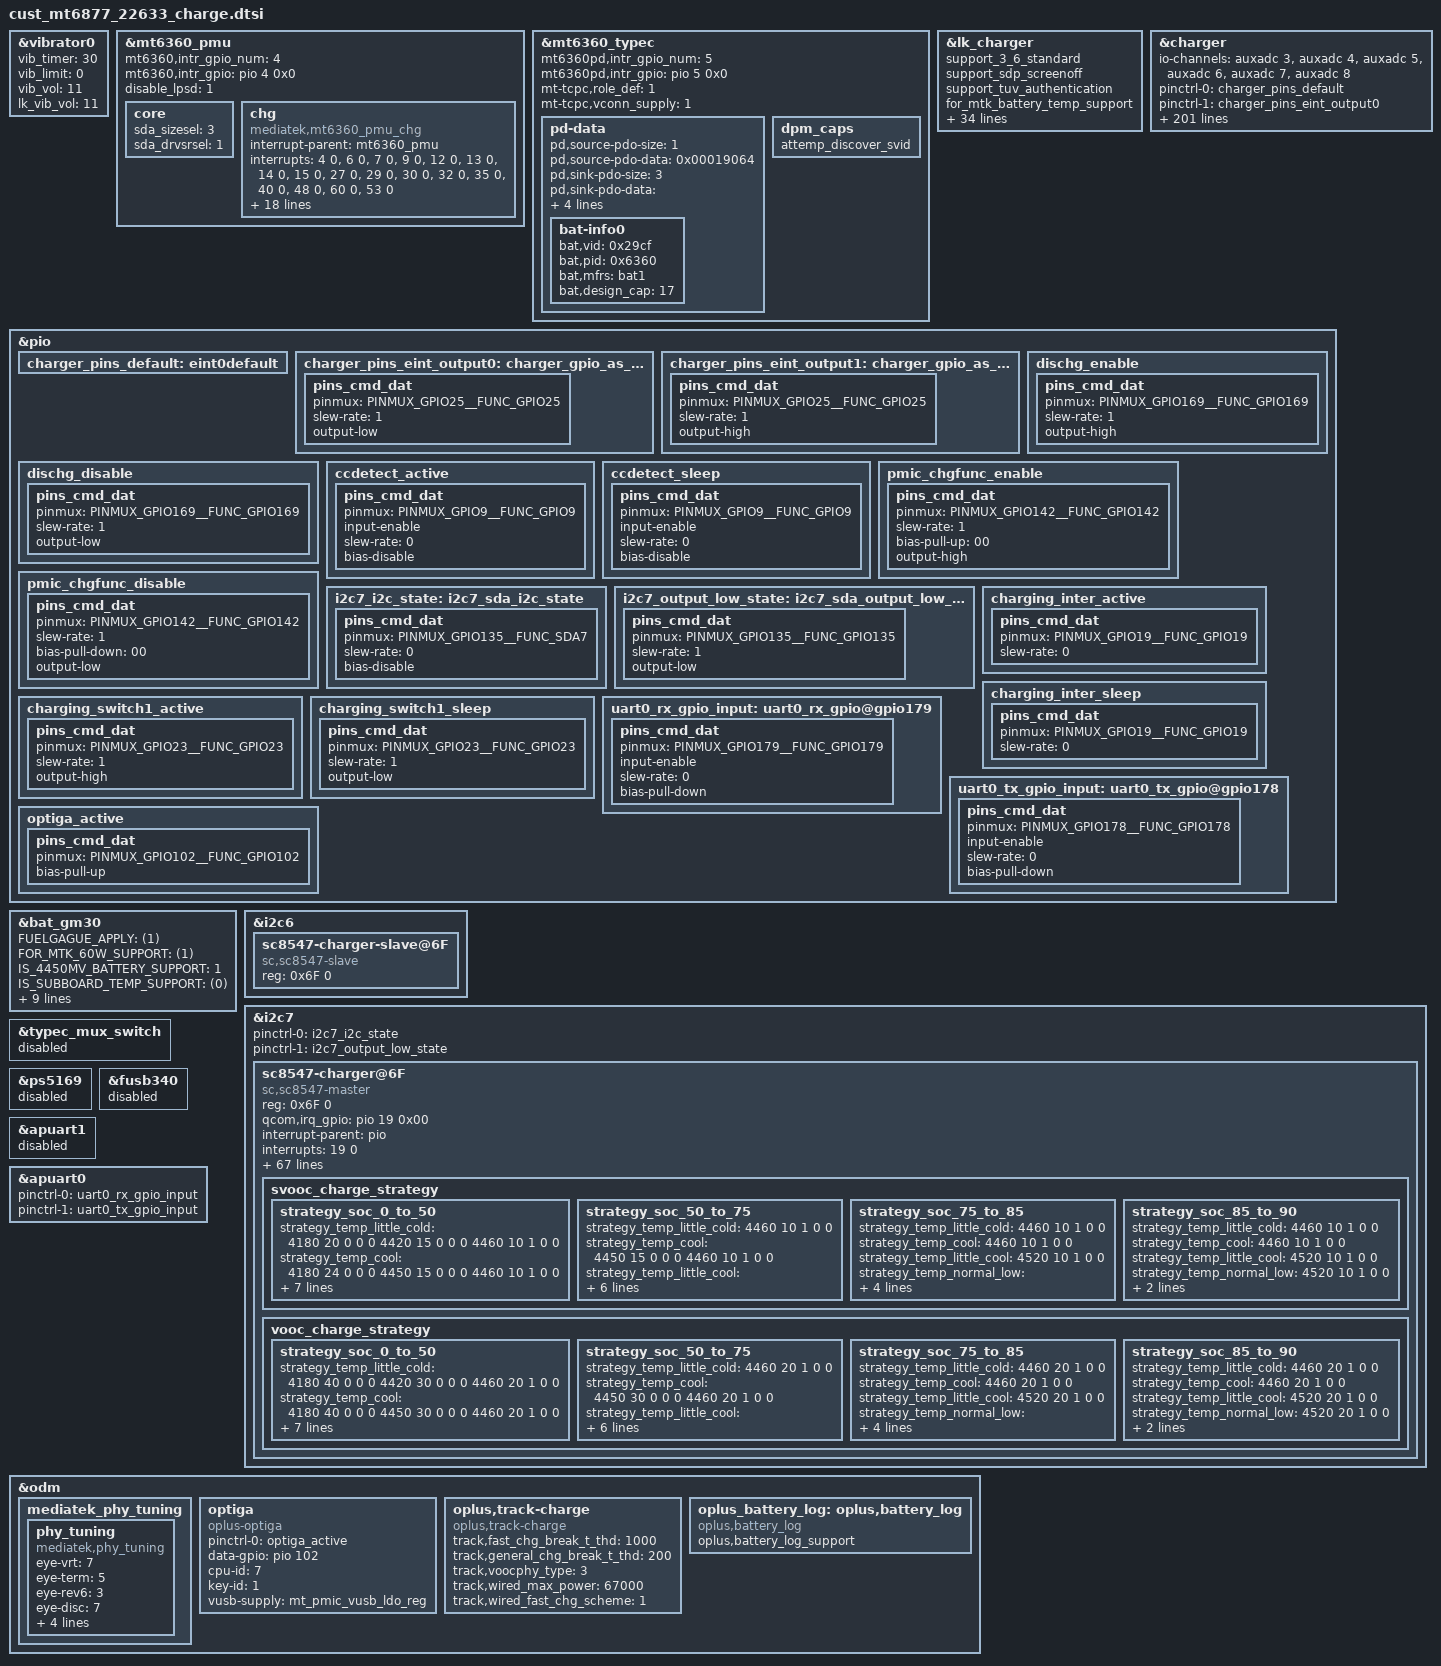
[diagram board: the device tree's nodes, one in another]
// SPDX-License-Identifier: GPL-2.0-only
/*
* Copyright (C) 2020-2021 Oplus. All rights reserved.
*/

//#ifdef OPLUS_FEATURE_CHG_BASIC
/*
 *
 * CPU:				--> MT6877
 * GPIO:
 * PERIEN_CHG_ENB		--> GPIO135(active - low)
 * MT6360_SCL			--> GPIO107(SCL5)
 * MT6360_SDA			--> GPIO108(SDA5)
 * EINT_SUBPMIC_IRQB    --> GPIO04
 * EINT_SUBPMIC_PD_IRQB --> GPIO05
 * CP1_SCL			    --> GPIO111(SCL7)
 * CP1_SDA			    --> GPIO112(SDA7)
 * CP2_SCL			    --> GPIO141(SCL9)
 * CP2_SDA			    --> GPIO142(SDA9)
 * CP1_INT			    --> GPIO19
 * USB_SWITCH1		    --> GPIO23
 * USB_SWITCH2 		    --> GPIO25
 * SEC_IC 		        --> GPIO102
 *
 * AP_UTXD0			    --> GPIO62
 * AP_URXD0			    --> GPIO61
 *
 * USB_ACC_INT			--> GPIO09
 * VBUS_SHORT			--> GPIO169
 *
 *
 * AUXADC:
 * 3				    --> AUX_IN2_CHARGER_NTC
 * 4				    --> AUX_IN2_BATTERY_NTC
 * 5				    --> AUX_IN4_USB_TEM_ADC_2
 * 6				    --> AUX_IN5_USB_TEM_ADC_1
 * 7				    --> AUX_IN3_BATT_ID(33W)/USB_CONN(67W)
 * 8				    --> AUX_IN6_NTC_BTB
 *
 *******************************************
 *
 * main pmic:			--> MT6365
 * charge pmic:			--> MT6360
 * charge ic:			--> MT6360
 * CP:				    --> HL7138
 * GAUGE:			    --> MT6365
 */

&vibrator0 {
	vib_timer = <30>;
	vib_limit = <0>;
	vib_vol= <11>;
	lk_vib_vol  = <11>;
	status = "okay";
};

&mt6360_pmu {
	mt6360,intr_gpio_num = <4>; /* direct defined GPIO num */
	mt6360,intr_gpio = <&pio 4 0x0>;
	disable_lpsd = <1>;

	core {
		sda_sizesel = <3>;
		sda_drvsrsel = <1>;
	};

	chg {
		compatible = "mediatek,mt6360_pmu_chg";
		interrupt-parent = <&mt6360_pmu>;
		interrupts = <4 0>, <6 0>, <7 0>, <9 0>,
				<12 0>, <13 0>, <14 0>, <15 0>,
				<27 0>, <29 0>, <30 0>, <32 0>,
				<35 0>, <40 0>, <48 0>, <60 0>,
				<53 0>;
		interrupt-names = "chg_treg_evt", "chg_mivr_evt",
				"pwr_rdy_evt", "chg_batsysuv_evt",
				"chg_vsysuv_evt", "chg_vsysov_evt",
				"chg_vbatov_evt", "chg_vbusov_evt",
				"chg_tmri", "chg_adpbadi",
				"chg_rvpi",  "chg_aiccmeasl",
				"wdtmri", "pumpx_donei",
				"attachi", "chrdet_ext_evt",
				"hvdcp_det";
		io-channels = <&adc 0>, <&adc 1>, <&adc 3>, <&adc 4>,
				<&adc 5>, <&adc 6>, <&adc 8>, <&adc 10>;
		io-channel-names = "USBID", "VBUSDIV5", "VSYS", "VBAT",
				"IBUS", "IBAT", "TEMP_JC", "TS";
		chg_name = "primary_chg";
		ichg = <2000000>;               /* uA */
		aicr = <500000>;                /* uA */
		mivr = <4400000>;               /* uV */
		cv = <4350000>;                 /* uA */
		ieoc = <150000>;                /* uA */
		safety_timer = <20>;            /* hour */
		ircmp_resistor = <25000>;       /* uohm */
		ircmp_vclamp = <32000>;         /* uV */
		en_te = <1>;
		en_wdt = <1>;
		aicc_once = <1>;
		post_aicc = <1>;
		batoc_notify = <0>;
		support_hvdcp;
		cdp_first_ignore;
	};
};

&mt6360_typec {
	mt6360pd,intr_gpio_num = <5>; /* direct defined GPIO num */
	mt6360pd,intr_gpio = <&pio 5 0x0>;
	mt-tcpc,role_def = <1>;  /* 0: Unknown, 1: SNK only, 2: SRC only, 3: DRP, 4: Try.SRC, 5: Try.SNK */
	mt-tcpc,vconn_supply  = <1>; /* 0: Never, 1: Always, 2: EMarkOnly, 3: StartOnly */
	pd-data {
		pd,source-pdo-size = <1>;
		pd,source-pdo-data = <0x00019064>; /* Fixed5V1A */

		pd,sink-pdo-size = <3>;
		pd,sink-pdo-data = <0x00019064 0x000190c8 0x0001912c>; /* Fixed5V1A Fixed5V2A Fixed5V3A */

		pd,id-vdo-size = <3>;
		pd,id-vdo-data = <0xd10029cf 0x0 0x63600000>; /* No DP, host + device */

		bat,nr = <1>;
		bat-info0 {
			bat,vid = <0x29cf>;
			bat,pid = <0x6360>;
			bat,mfrs = "bat1";
			bat,design_cap = <17>; /*3.87V*4390mAh=16.98Wh*/
		};
	};

	dpm_caps {
		attemp_discover_svid;
	};
};

&lk_charger{
	support_3_6_standard;
	support_sdp_screenoff;
	support_tuv_authentication;
	for_mtk_battery_temp_support;
	sub_board_temp_support;
	sub_board_temp_adc_channel = <4>;
	max_charger_voltage = <9900000>;
	support_new_charger_stander;
	usb_charger_current = <500000>;
	ac_charger_input_current = <2000000>;
	non_std_ac_charger_current = <2000000>;
	charging_host_charger_current = <1500000>;
	precharge_1_step_current = <350>;

	cold_bat_decidegc = <10>;  /*-10C~0C*/
	dcp_temp_cold_fastchg_current = <300>;
	usb_temp_cold_fastchg_current = <300>;
	cdp_temp_cold_fastchg_current = <300>;

	little_cold_bat_decidegc = <0>;    /*0C~5C*/
	dcp_temp_little_cold_fastchg_current = <800>;
	usb_temp_little_cold_fastchg_current = <500>;
	cdp_temp_little_cold_fastchg_current = <800>;

	cool_bat_decidegc = <5>;  /*5C~12C*/
	dcp_temp_cool_fastchg_current = <1600>;
	usb_temp_cool_fastchg_current = <600>;
	cdp_temp_cool_fastchg_current = <1600>;

	little_cool_bat_decidegc = <12>;  /*12C~16C*/
	dcp_temp_little_cool_fastchg_current = <2200>;
	usb_temp_little_cool_fastchg_current = <600>;
	cdp_temp_little_cool_fastchg_current = <1600>;

	normal_bat_decidegc = <16>;       /*16C~45C*/
	dcp_temp_normal_fastchg_current = <2200>;
	usb_temp_normal_fastchg_current = <600>;
	cdp_temp_normal_fastchg_current = <1600>;

	warm_bat_decidegc = <45>;    /*45C~53C*/
	dcp_temp_warm_fastchg_current = <2200>;
	usb_temp_warm_fastchg_current = <600>;
	cdp_temp_warm_fastchg_current = <1600>;

	hot_bat_decidegc = <53>;
};

&charger {
	io-channels = <&auxadc 3>,
		<&auxadc 4>,
		<&auxadc 5>,
		<&auxadc 6>,
		<&auxadc 7>,
		<&auxadc 8>;

	io-channel-names = "auxadc3-chargeric_temp",
		"auxadc6-subboard_temp",
		"auxadc4-usb_temp_v_l",
		"auxadc5-usb_temp_v_r",
		"usbcon_temp",
		"batcon_temp";

	pinctrl-names = "default", "charger_gpio_as_output_low", "charger_gpio_as_output_high", "dischg_enable",
		"dischg_disable", "ccdetect_active", "ccdetect_sleep", "pmic_chgfunc_enable", "pmic_chgfunc_disable";
	pinctrl-0 = <&charger_pins_default>;
	pinctrl-1 = <&charger_pins_eint_output0>;
	pinctrl-2 = <&charger_pins_eint_output1>;
	pinctrl-3 = <&dischg_enable>;
	pinctrl-4 = <&dischg_disable>;
	pinctrl-5 = <&ccdetect_active>;
	pinctrl-6 = <&ccdetect_sleep>;
	pinctrl-7 = <&pmic_chgfunc_enable>;
	pinctrl-8 = <&pmic_chgfunc_disable>;

	qcom,input_current_charger_ma = <2000>;
	qcom,pd_input_current_charger_ma = <1500>;
	qcom,qc_input_current_charger_ma = <1500>;
	qcom,input_current_usb_ma = <500>;
	qcom,input_current_cdp_ma = <1500>;
	qcom,input_current_camera_ma = <1200>;
	qcom,input_current_calling_ma = <1500>;

	qcom,led_warm_bat_decidegc = <350>;
	qcom,led_high_bat_decidegc = <370>;
	qcom,input_current_led_ma = <1200>;
	qcom,input_current_led_ma_high = <1200>;
	qcom,input_current_led_ma_warm = <1500>;
	qcom,input_current_led_ma_normal = <2300>;
	qcom,input_current_led_ma_forcmcc = <500>;
	qcom,input_current_led_ma_limit_high = <1200>;

	qcom,vooc_temp_bat_normal_decidegc = <350>;
	qcom,vooc_temp_bat_warm_decidegc = <370>;
	qcom,vooc_temp_bat_hot_decidegc = <510>;
	qcom,input_current_vooc_led_ma_high = <1200>;
	qcom,input_current_vooc_led_ma_warm = <1800>;
	qcom,input_current_vooc_led_ma_normal = <3600>;
	qcom,input_current_vooc_ma_normal = <3600>;
	qcom,input_current_vooc_ma_warm = <3200>;
	qcom,input_current_vooc_ma_high = <2200>;

	qcom,overtemp_bat_decidegc = <350>;
	qcom,iterm_disabled = <0>;
	//sw_full_count = <25>;
	qcom,iterm_ma = <250>;
	qcom,recharge-mv = <100>;

	qcom,batt_capacity_mah = <5000>; /*typical capacity*/
	//qcom,batt_capacity_mah = <4880>; /*rated capacity*/
	qcom,usb_high_than_bat_decidegc = <168>;

	qcom,removed_bat_decidegc = <390>;  /* < -39C */

	qcom,cold_bat_decidegc = <100>;  /* -10C ~ 0C */
	qcom,temp_cold_vfloat_mv = <4465>;
	qcom,temp_cold_fastchg_current_ma = <1200>;

	qcom,little_cold_bat_decidegc = <0>;    /* 0C ~ 5C */
	qcom,temp_little_cold_vfloat_mv = <4465>;
	qcom,temp_little_cold_fastchg_current_ma_high = <2200>;
	qcom,temp_little_cold_fastchg_current_ma_low = <2200>;
	qcom,temp_little_cold_fastchg_current_ma = <1076>;
	qcom,qc_temp_little_cold_fastchg_current_ma_high = <2594>;
	qcom,qc_temp_little_cold_fastchg_current_ma_low = <3300>;
	qcom,pd_temp_little_cold_fastchg_current_ma_high = <2594>;
	qcom,pd_temp_little_cold_fastchg_current_ma_low = <3300>;

	qcom,cool_bat_decidegc = <50>;  /* 5C ~ 12C */
	qcom,temp_cool_vfloat_mv = <4465>;
	qcom,temp_cool_fastchg_current_ma_high = <2200>;
	qcom,temp_cool_fastchg_current_ma_low = <2200>;
	qcom,qc_temp_cool_fastchg_current_ma_high = <3300>;
	qcom,qc_temp_cool_fastchg_current_ma_low = <3300>;
	qcom,pd_temp_cool_fastchg_current_ma_high = <3300>;
	qcom,pd_temp_cool_fastchg_current_ma_low = <3300>;

	qcom,little_cool_bat_decidegc = <120>;  /* 12C ~ 16C */
	qcom,temp_little_cool_vfloat_mv = <4465>;
	qcom,temp_little_cool_fastchg_current_ma = <2200>;
	qcom,pd_temp_little_cool_fastchg_current_ma = <3300>;
	qcom,qc_temp_little_cool_fastchg_current_ma = <3300>;

	qcom,normal_bat_decidegc = <160>;       /* 16C ~ 45C */
	qcom,temp_normal_vfloat_mv = <4465>;
	qcom,temp_normal_fastchg_current_ma = <2200>;
	qcom,pd_temp_normal_fastchg_current_ma = <3300>;
	qcom,qc_temp_normal_fastchg_current_ma = <3300>;

	qcom,warm_bat_decidegc = <450>;         /* 45C ~ 53C */ /*8pin Bat Vooc project need add 3 degree C*/
	qcom,temp_warm_vfloat_mv = <4130>;
	qcom,temp_warm_fastchg_current_ma = <2200>;
	qcom,pd_temp_warm_fastchg_current_ma = <2200>;
	qcom,qc_temp_warm_fastchg_current_ma = <2200>;
	qcom,temp_warm_fastchg_current_ma_led_on = <1000>;

	qcom,hot_bat_decidegc = <530>;  /* > 53C */

	qcom,non_standard_vfloat_mv = <3980>;
	qcom,non_standard_fastchg_current_ma = <512>;
	qcom,support_subboard_ntc;

	qcom,short_c_bat_cv_mv = <4330>;
	qcom,short_c_bat_vfloat_mv = <3800>;
	qcom,short_c_bat_fastchg_current_ma = <512>;
	qcom,short_c_bat_vfloat_sw_limit = <3750>;

	qcom,cold_vfloat_sw_limit = <4415>;
	qcom,little_cold_vfloat_sw_limit = <4415>;
	qcom,cool_vfloat_sw_limit = <4415>;
	qcom,little_cool_vfloat_sw_limit = <4415>;
	qcom,normal_vfloat_sw_limit = <4415>;
	qcom,warm_vfloat_sw_limit = <4080>;
	qcom,non_standard_vfloat_sw_limit = <3930>;

	qcom,max_chg_time_sec = <72000>;
	qcom,charger_hv_thr = <10000>;
	qcom,charger_recv_thr = <9800>;
	qcom,charger_lv_thr = <3400>;
	qcom,vbatt_full_thr = <4465>;
	qcom,vbatt_hv_thr = <4600>;

	qcom,vfloat_step_mv = <8>;
	qcom,non_standard_vfloat_over_sw_limit = <3990>;
	qcom,cold_vfloat_over_sw_limit = <4475>;
	qcom,little_cold_vfloat_over_sw_limit = <4475>;
	qcom,cool_vfloat_over_sw_limit = <4475>;
	qcom,little_cool_vfloat_over_sw_limit = <4475>;
	qcom,normal_vfloat_over_sw_limit = <4475>;
	qcom,warm_vfloat_over_sw_limit = <4140>;

	qcom,usbtemp_batt_temp_low = <50>;
	qcom,usbtemp_batt_temp_high = <50>;
	qcom,usbtemp_ntc_temp_low = <57>;
	qcom,usbtemp_ntc_temp_high = <69>;
	qcom,usbtemp_temp_gap_low_with_batt_temp = <7>;
	qcom,usbtemp_temp_gap_high_with_batt_temp = <12>;
	qcom,usbtemp_temp_gap_low_without_batt_temp = <12>;
	qcom,usbtemp_temp_gap_high_without_batt_temp = <24>;
	qcom.usbtemp_rise_fast_temp_low = <3>;
	qcom.usbtemp_rise_fast_temp_high = <3>;
	qcom.usbtemp_rise_fast_temp_count_low = <30>;
	qcom.usbtemp_rise_fast_temp_count_high = <20>;

	qcom,usbtemp_cool_down_ntc_low = <54>;
	qcom,usbtemp_cool_down_ntc_high = <65>;
	qcom,usbtemp_cool_down_gap_low = <12>;
	qcom,usbtemp_cool_down_gap_high = <20>;
	qcom,usbtemp_cool_down_recover_ntc_low = <48>;
	qcom,usbtemp_cool_down_recover_ntc_high = <60>;
	qcom,usbtemp_cool_down_recover_gap_low = <6>;
	qcom,usbtemp_cool_down_recover_gap_high = <15>;

	qcom,vbatt_power_off = <3300>;
	qcom,vbatt_soc_1 = <3410>;
	qcom,vooc_project = <13>;
	qcom,vbatt_num = <1>;
	qcom,new_ui_warning_support;
	qcom,smart_charging_screenoff;
	qcom,smart_charge_version = <1>;

	qcom,normal_vterm_hw_inc = <18>;
	qcom,non_normal_vterm_hw_inc = <18>;
	qcom,usbtemp_batttemp_gap = <12>;

	qcom,ff1_normal_fastchg_ma = <1500>;
	qcom,ff1_warm_fastchg_ma = <1600>;	/* 35C ~ 40c */
	qcom,ff1_exit_step_ma = <150>;
	qcom,ff1_warm_exit_step_ma = <150>;
	qcom,ffc2_normal_fastchg_ma = <1350>;/*12C~35c*/
	qcom,ffc2_warm_fastchg_ma = <1600>;	/* 35C ~ 40c */
	qcom,ffc2_temp_warm_decidegc = <350>;
	qcom,ffc2_temp_high_decidegc = <400>;
	qcom,ffc2_temp_low_decidegc = <160>;
	qcom,ffc2_exit_step_ma = <150>;
	qcom,ffc2_warm_exit_step_ma = <150>;

	qcom,ffc_normal_vfloat_sw_limit = <4515>;
	qcom,ffc2_normal_vfloat_sw_limit = <4515>;
	qcom,ffc_warm_vfloat_sw_limit = <4515>;
	qcom,ffc2_warm_vfloat_sw_limit = <4515>;
	qcom,ffc_temp_normal_vfloat_mv = <4580>;
	qcom,ffc_normal_vfloat_over_sw_limit = <4580>;
	qcom,ffc2_temp_normal_vfloat_mv = <4580>;
	qcom,ffc2_normal_vfloat_over_sw_limit = <4580>;

	qcom,default_iterm_ma = <250>;
	qcom,default_temp_normal_fastchg_current_ma = <2200>;
	qcom,default_normal_vfloat_sw_limit = <4415>;
	qcom,default_temp_normal_vfloat_mv = <4465>;
	qcom,default_normal_vfloat_over_sw_limit = <4475>;
	qcom,default_temp_little_cool_fastchg_current_ma = <2200>;
	qcom,default_little_cool_vfloat_sw_limit = <4415>;
	qcom,default_temp_little_cool_vfloat_mv = <4465>;
	qcom,default_little_cool_vfloat_over_sw_limit = <4475>;
	//qcom,usbtemp_dischg_by_pmic;
	qcom,support_usbtemp_protect_v2;
	oplus,pdqc_9v_voltage_adaptive;
	//for PD9V or QC9V
	qcom,vbatt_pdqc_to_5v_thr = <4500>;
	qcom,vbatt_pdqc_to_9v_thr = <4500>;

	//for control:
	//qcom,suspend_after_full;
	qcom,support_abnormal_adapter;
	qcom,check_batt_full_by_sw;
	qcom,chg_ctrl_by_lcd;
	qcom,chg_ctrl_by_camera;
	qcom,chg_ctrl_by_calling;
	qcom,sw_vfloat_over_protect_enable;
	qcom,ffc_support;
	qcom,chargerid_vol_disable;
	qcom,support_ntc_01c_precision;
	qcom,voocphy_support = <(3)>; // AP_DUAL_CP_VOOCPHY
	qcom,external_authenticate;
	qcom,chargerid_support;
	qcom,vooc_show_ui_soc_decimal;
	qcom,ui_soc_decimal_speedmin = <20>;//2A
	//USB temperature
	 qcom,g_rap_pull_up_r0 = <390000>;

	//GPIO config:
	qcom,chargerid_switch-gpio = <&pio 25 0x00>;
	qcom,dischg-gpio = <&pio 169 0x00>;
	qcom,ccdetect-gpio = <&pio 9 0x00>;
	qcom,pmic_chgfunc = <&pio 142 0x00>;

	qcom,vooc-max-input-volt-support = <11000>;     //11V
	qcom,vooc-max-input-current-support = <6000>;   //6A
};

&pio {
	charger_pins_default: eint0default {
	};

	charger_pins_eint_output0: charger_gpio_as_output_low {
		pins_cmd_dat {
			pinmux = <PINMUX_GPIO25__FUNC_GPIO25>;
			slew-rate = <1>;
			output-low;
		};
	};

	charger_pins_eint_output1: charger_gpio_as_output_high {
		pins_cmd_dat {
			pinmux = <PINMUX_GPIO25__FUNC_GPIO25>;
			slew-rate = <1>;
			output-high;
		};
	};

	dischg_enable: dischg_enable {
		pins_cmd_dat {
			pinmux = <PINMUX_GPIO169__FUNC_GPIO169>;
			slew-rate = <1>;
			output-high;
		};
	};

	dischg_disable: dischg_disable {
		pins_cmd_dat {
			pinmux = <PINMUX_GPIO169__FUNC_GPIO169>;
			slew-rate = <1>;
			output-low;
		};
	};

	ccdetect_active: ccdetect_active {
		pins_cmd_dat {
			pinmux = <PINMUX_GPIO9__FUNC_GPIO9>;
			input-enable;
			slew-rate = <0>;
			bias-disable;
		};
	};
	ccdetect_sleep: ccdetect_sleep {
		pins_cmd_dat {
			pinmux = <PINMUX_GPIO9__FUNC_GPIO9>;
			input-enable;
			slew-rate = <0>;
			bias-disable;
		};
	};
	pmic_chgfunc_enable: pmic_chgfunc_enable {
		pins_cmd_dat {
			pinmux = <PINMUX_GPIO142__FUNC_GPIO142>;
			slew-rate = <1>;//0:input direction 1:output direction
			bias-pull-up = <00>;
			output-high;
		};
	};

	pmic_chgfunc_disable: pmic_chgfunc_disable {
		pins_cmd_dat {
			pinmux = <PINMUX_GPIO142__FUNC_GPIO142>;    /*6360 主充CHG_ENB*/
			slew-rate = <1>;
			bias-pull-down = <00>;
			output-low;
		};
	};
};

&bat_gm30 {
	FUELGAGUE_APPLY = <(1)>;
	FOR_MTK_60W_SUPPORT = <(1)>;
	IS_4450MV_BATTERY_SUPPORT = <1>;
	IS_SUBBOARD_TEMP_SUPPORT = <(0)>;
	EMBEDDED_SEL = <(1)>;
	R_FG_VALUE = <(2)>;
	CAR_TUNE_VALUE = <(99)>;

	KEEP_100_PERCENT = <(3)>;
	g_FG_PSEUDO100_T0 = <(95)>;
	g_FG_PSEUDO100_T1 = <(95)>;
	g_FG_PSEUDO100_T2 = <(94)>;
	g_FG_PSEUDO100_T3 = <(92)>;
	g_FG_PSEUDO100_T4 = <(76)>;

	#include "mediatek/bat_setting/mt6877_battery_table_22633.dtsi"
	#include "mediatek/bat_setting/mt6877_battery_prop_dim2_ext_22633.dtsi"
};

&i2c6 {
	sc8547-charger-slave@6F{
		status = "okay";
		compatible = "sc,sc8547-slave";
		reg = <0x6F 0>;

		// qcom,irq_gpio = <&pio 55 0x00>;
		// interrupt-parent = <&pio>;
		// interrupts = <55 0>;
	};
};

&i2c7 {
	pinctrl-names = "i2c-state", "output-low-state";
	pinctrl-0 = <&i2c7_i2c_state>;
	pinctrl-1 = <&i2c7_output_low_state>;
};
&pio {
	i2c7_i2c_state: i2c7_sda_i2c_state {
		pins_cmd_dat {
			pinmux = <PINMUX_GPIO135__FUNC_SDA7>;
			slew-rate = <0>;
			bias-disable;
		};
	};
	i2c7_output_low_state: i2c7_sda_output_low_state {
		pins_cmd_dat {
			pinmux = <PINMUX_GPIO135__FUNC_GPIO135>;
			slew-rate = <1>;
			output-low;
		};
	};
};

&i2c7 {
	sc8547-charger@6F{
		status = "okay";
		compatible = "sc,sc8547-master";
		reg = <0x6F 0>;

		qcom,irq_gpio = <&pio 19 0x00>;
		interrupt-parent = <&pio>;
		interrupts = <19 0>;

		pinctrl-names = "switch1_act_switch2_act", "switch1_sleep_switch2_sleep",
				"charging_inter_active", "charging_inter_sleep";
		pinctrl-0 = <&charging_switch1_active>;
		pinctrl-1 = <&charging_switch1_sleep>;
		pinctrl-2 = <&charging_inter_active>;
		pinctrl-3 = <&charging_inter_sleep>;

		qcom,charging_switch1-gpio = <&pio 23 0x00>;

		qcom,copycat_vooc_support;
		qcom,voocphy_dual_cp_support;
		qcom,slave_cp_enable_thr = <1900>;		//2000-100mA
		qcom,slave_cp_disable_thr_high = <1600>;	//1500+100mA
		qcom,voocphy_current_default = <61>;
		qcom,abnormal_adapter_current = <122 50 50 50 40 40 30 30 20 20>;

		qcom,svooc_cool_down_current_limit = <122 20 20 24 30 34 40 44 50 54 60 64 70 74>;
		qcom,vooc_cool_down_current_limit = <61 20 20 24 30 34 40 44 50 54 60 64 70 74>;

		qcom,vooc_multistep_initial_batt_temp = <1000>;
		qcom,vooc_little_cool_temp = <160>;
		qcom,vooc_cool_temp = <120>;
		qcom,vooc_little_cold_temp = <50>;
		qcom,vooc_normal_low_temp = <350>;
		qcom,vooc_strategy_normal_current = <122>;
		qcom,vooc_normal_to_little_cool_current = <100>;
		qcom,vooc_batt_over_high_temp = <510>;
		qcom,vooc-low-temp = <0>;
		qcom,vooc-high-temp = <500>;
		qcom,vooc-low-soc = <0>;
		qcom,vooc-high-soc = <90>;
		qcom,vooc-normal-high-temp = <430>;
		qcom,vooc-warm-allow-vol = <4000>;
		qcom,vooc-warm-allow-soc = <50>;

		qcom,vooc_strategy1_batt_high_temp0 = <395>;
		qcom,vooc_strategy1_batt_high_temp1 = <420>;
		qcom,vooc_strategy1_batt_high_temp2 = <440>;
		qcom,vooc_strategy1_batt_low_temp2 = <420>;
		qcom,vooc_strategy1_batt_low_temp1 = <395>;
		qcom,vooc_strategy1_batt_low_temp0 = <385>;

		qcom,vooc_strategy1_high_current0 = <80>;
		qcom,vooc_strategy1_high_current1 = <60>;
		qcom,vooc_strategy1_high_current2 = <40>;
		qcom,vooc_strategy1_low_current2 = <40>;
		qcom,vooc_strategy1_low_current1 = <60>;
		qcom,vooc_strategy1_low_current0 = <80>;

		qcom,voocphy_freq_mincore = <1800000>;
		qcom,voocphy_freq_midcore = <1800000>;
		qcom,voocphy_freq_maxcore = <1800000>;
		qcom,voocphy_current_change_timeout = <100>;

		qcom,voocphy_ibat_over_current = <13500>;
		qcom,voocphy_svooc_cp_max_ibus = <3500>;
		qcom,voocphy_vooc_cp_max_ibus = <3500>;
		qcom,voocphy_cp_max_ibus = <3500>;

		qcom,vooc_little_cold_full_voltage = <4460>;
		qcom,vooc_cool_full_voltage = <4460>;
		qcom,vooc_warm_full_voltage = <4130>;
		qcom,vooc_1time_full_voltage = <4530>;
		qcom,vooc_ntime_full_voltage = <4520>;
		qcom,low_curr_full_t1 = <120>;
		qcom,low_curr_full_t2 = <350>;
		qcom,low_curr_full_t3 = <430>;
		qcom,range1_low_curr_full = <1350 4520
						1250 4515
						1150 4500
						1050 4490
						950  4480>;
		qcom,range2_low_curr_full = <1550 4520
						1450 4515
						1350 4500
						1250 4490
						1150 4480>;
		svooc_batt_sys_curve = <0 1 0 1 0 0 0	// 4000mA
					1 1 1 1 0 0 0	// 4604mV
					0 0 1 1 0 1 0	// 2600mA
					1 1 1 1 0 0 0	// 4604mV
					0 0 0 1 0 1 1	// 1100mA
					1 1 1 1 0 0 0>;	// 4604mV

		vooc_batt_sys_curve =  <0 1 0 1 0 0 0	// 4000mA
					1 1 1 1 0 0 0	// 4604mV
					0 0 1 1 0 1 0	// 2600mA
					1 1 1 1 0 0 0	// 4604mV
					0 0 0 1 0 1 1	// 1100mA
					1 1 1 1 0 0 0>;	// 4604mV

		svooc_charge_strategy {
			strategy_soc_0_to_50 {
				strategy_temp_little_cold =	<4180 20 0 0 0
                                                                 4420 15 0 0 0
								 4460 10 1 0 0>;
				strategy_temp_cool =	<4180 24 0 0 0
                                                                 4450 15 0 0 0
								 4460 10 1 0 0>;
				strategy_temp_little_cool =	<4180 40 0 0 0
								 4480 30 0 0 0
								 4480 25 0 0 0
								 4510 20 0 0 0
								 4510 15 0 0 0
								 4520 10 1 0 0>;
				strategy_temp_normal_low =	<4200 61 0 120 0 //min*60*1000/500
								 4200 50 0 360 0 //min*60*1000/500
								 4350 40 0 1200 0
								 4480 30 0 0 0
								 4480 25 0 0 0
								 4510 20 0 0 0
								 4510 15 0 0 0
								 4520 10 1 0 0>;
				strategy_temp_normal_high =	<4200 61 0 120 0 //min*60*1000/500
								 4200 50 0 360 0 //min*60*1000/500
								 4350 40 0 1200 0
								 4480 30 0 0 0
								 4480 25 0 0 0
								 4510 20 0 0 0
								 4510 15 0 0 0
								 4520 10 1 0 0>;
				strategy_temp_warm = <4130 10 1 0 0>;
			};

			strategy_soc_50_to_75 {
				strategy_temp_little_cold =	<4460 10 1 0 0>;
				strategy_temp_cool =	<4450 15 0 0 0
								 4460 10 1 0 0>;
				strategy_temp_little_cool =	<4510 20 0 0 0
								 4510 15 0 0 0
								 4520 10 1 0 0>;
				strategy_temp_normal_low =	<4480 30 0 0 0
								 4480 25 0 0 0
								 4510 20 0 0 0
                                                                 4510 15 0 0 0
								 4520 10 1 0 0>;
				strategy_temp_normal_high =	<4480 25 0 0 0
								 4510 20 0 0 0
								 4510 15 0 0 0
								 4520 10 1 0 0>;
				strategy_temp_warm = <4130 10 1 0 0>;
			};

			strategy_soc_75_to_85 {
				strategy_temp_little_cold =	<4460 10 1 0 0>;
				strategy_temp_cool =	<4460 10 1 0 0>;
				strategy_temp_little_cool =	<4520 10 1 0 0>;
				strategy_temp_normal_low =	<4510 15 0 0 0
								 4520 10 1 0 0>;
				strategy_temp_normal_high =	<4510 15 0 0 0
								 4520 10 1 0 0>;
				strategy_temp_warm = <4130 10 1 0 0>;
			};

			strategy_soc_85_to_90 {
				strategy_temp_little_cold =	<4460 10 1 0 0>;
				strategy_temp_cool =	<4460 10 1 0 0>;
				strategy_temp_little_cool =	<4520 10 1 0 0>;
				strategy_temp_normal_low =	<4520 10 1 0 0>;
				strategy_temp_normal_high =	<4520 10 1 0 0>;
				strategy_temp_warm = <4130 10 1 0 0>;
			};
		};

		vooc_charge_strategy {
			strategy_soc_0_to_50 {
				strategy_temp_little_cold =	<4180 40 0 0 0
                                                                 4420 30 0 0 0
								 4460 20 1 0 0>;
				strategy_temp_cool =	<4180 40 0 0 0
								 4450 30 0 0 0
								 4460 20 1 0 0>;
				strategy_temp_little_cool =	<4480 60 0 0 0
								 4480 50 0 0 0
								 4480 40 0 0 0
								 4480 30 0 0 0
								 4520 20 1 0 0>;
				strategy_temp_normal_low =	<4480 60 0 0 0
								 4480 50 0 0 0
								 4510 40 0 0 0
								 4510 30 0 0 0
								 4520 20 1 0 0>;
				strategy_temp_normal_high =	<4480 60 0 0 0
								 4480 50 0 0 0
								 4510 40 0 0 0
								 4510 30 0 0 0
								 4520 20 1 0 0>;
				strategy_temp_warm = <4130 20 1 0 0>;
			};

			strategy_soc_50_to_75 {
				strategy_temp_little_cold =	<4460 20 1 0 0>;
				strategy_temp_cool =	<4450 30 0 0 0
								 4460 20 1 0 0>;
				strategy_temp_little_cool =	<4510 40 0 0 0
								 4510 30 0 0 0
								 4520 20 1 0 0>;
				strategy_temp_normal_low =	<4480 60 0 0 0
								 4480 50 0 0 0
                                                                 4510 40 0 0 0
								 4510 30 0 0 0
								 4520 20 1 0 0>;
				strategy_temp_normal_high =	<4480 50 0 0 0
								 4510 40 0 0 0
								 4510 30 0 0 0
								 4520 20 1 0 0>;
				strategy_temp_warm = <4130 20 1 0 0>;
			};

			strategy_soc_75_to_85 {
				strategy_temp_little_cold =	<4460 20 1 0 0>;
				strategy_temp_cool =	<4460 20 1 0 0>;
				strategy_temp_little_cool =	<4520 20 1 0 0>;
				strategy_temp_normal_low =	<4510 30 0 0 0
								 4520 20 1 0 0>;
				strategy_temp_normal_high =	<4510 30 0 0 0
								 4520 20 1 0 0>;
				strategy_temp_warm = <4130 20 1 0 0>;
			};

			strategy_soc_85_to_90 {
				strategy_temp_little_cold =	<4460 20 1 0 0>;
				strategy_temp_cool =	<4460 20 1 0 0>;
				strategy_temp_little_cool =	<4520 20 1 0 0>;
				strategy_temp_normal_low =	<4520 20 1 0 0>;
				strategy_temp_normal_high =	<4520 20 1 0 0>;
				strategy_temp_warm = <4130 20 1 0 0>;
			};
		};
	};
};

&typec_mux_switch {
	status = "disabled";
};

&ps5169{
	status = "disabled";
};

&fusb340 {
	status = "disabled";
};

&pio {
	charging_inter_active: charging_inter_active {
		pins_cmd_dat {
			pinmux = <PINMUX_GPIO19__FUNC_GPIO19>;
			slew-rate = <0>;
		};
	};

	charging_inter_sleep: charging_inter_sleep {
		pins_cmd_dat {
			pinmux = <PINMUX_GPIO19__FUNC_GPIO19>;
			slew-rate = <0>;
		};
	};

	charging_switch1_active: charging_switch1_active {
		pins_cmd_dat {
			pinmux = <PINMUX_GPIO23__FUNC_GPIO23>;
			slew-rate = <1>;
			output-high;
		};
	};

	charging_switch1_sleep: charging_switch1_sleep {
		pins_cmd_dat {
			pinmux = <PINMUX_GPIO23__FUNC_GPIO23>;
			slew-rate = <1>;
			output-low;
		};
	};
};

&apuart1 {
	status = "disabled";
};

&apuart0 {
	pinctrl-names = "uart0_rx_gpio",
			"uart0_tx_gpio";
	pinctrl-0 = <&uart0_rx_gpio_input>;
	pinctrl-1 = <&uart0_tx_gpio_input>;
	status = "okay";
};

&pio {
	uart0_rx_gpio_input:uart0_rx_gpio@gpio179 {
		pins_cmd_dat {
			pinmux = <PINMUX_GPIO179__FUNC_GPIO179>;
			input-enable;
			slew-rate = <0>;
			bias-pull-down;
		};
	};
	uart0_tx_gpio_input:uart0_tx_gpio@gpio178 {
		pins_cmd_dat {
			pinmux = <PINMUX_GPIO178__FUNC_GPIO178>;
			input-enable;
			slew-rate = <0>;
			bias-pull-down;
		};
	};
};

&odm {
	mediatek_phy_tuning: mediatek_phy_tuning {
		phy_tuning {
			compatible = "mediatek,phy_tuning";
			eye-vrt = <7>;
			eye-term = <5>;
			eye-rev6 = <3>;
			eye-disc = <7>;
			host-eye-vrt = <6>;
			host-eye-term = <3>;
			host-eye-rev6 = <3>;
			host-eye-disc = <0xf>;
		};
	};

	optiga {
		compatible = "oplus-optiga";
		status = "ok";
		pinctrl-names = "optiga_active";
		pinctrl-0 = <&optiga_active>;
		data-gpio = <&pio 102 0x00>;
		cpu-id = <7>;
		key-id = <1>;
		vusb-supply = <&mt_pmic_vusb_ldo_reg>;
	};
	oplus,track-charge {
		compatible = "oplus,track-charge";
		track,fast_chg_break_t_thd = <1000>;
		track,general_chg_break_t_thd = <200>;
		track,voocphy_type = <3>;
		track,wired_max_power = <67000>;
		track,wired_fast_chg_scheme = <1>;
	};
	oplus_battery_log: oplus,battery_log {
		compatible = "oplus,battery_log";
		oplus,battery_log_support;
	};
};

&pio {
	optiga_active: optiga_active {
		pins_cmd_dat {
			pinmux = <PINMUX_GPIO102__FUNC_GPIO102>;
			//slew-rate = <1>;
			bias-pull-up;
		};
	};
};
//#endif /*OPLUS_FEATURE_CHG_BASIC*/
